# MK70F15 register map
Vendor: Freescale Semiconductor, Inc.; Series: Kinetis_K; File version: 1.6
CPU: CM4 r0p1, little endian, no MPU, FPU, VTOR, 4 interrupt priority bits
Registers are 32-bit, read-write, reset 0x0 unless marked. A register's access mark holds for its fields unless they carry their own. Offsets are from the block's base; [hi:lo] are bit positions; {n}, {i} and the like mark numbered series; 'fields as' and 'values as' point back to an identical list.

## DDR — DRAM Controller
Base 0x400AE000; register names take the prefix DDR_
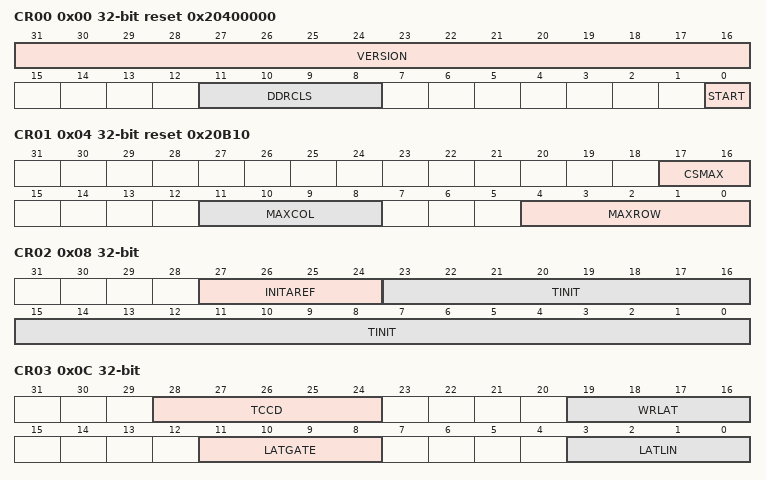
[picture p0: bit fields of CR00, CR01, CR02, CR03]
0x00 CR00 reset 0x20400000 — DDR Control Register 0
  [31:16] VERSION ro
  [11:8] DDRCLS — DRAM Class
    0=DDR; 1=LPDDR; 4=DDR2
  [0] START
0x04 CR01 ro reset 0x20B10 — DDR Control Register 1
  [17:16] CSMAX — Chip Select Maximum
    0=Zero; 1=One; 2=Two
  [11:8] MAXCOL — Maximum Column
    0=0; 1=1; 11=11
  [4:0] MAXROW — Maxmum Row
0x08 CR02 — DDR Control Register 2
  [27:24] INITAREF — Initialization Auto-Refresh
  [23:0] TINIT — Time Initialization
0x0C CR03 — DDR Control Register 3
  [28:24] TCCD — Time CAS-to-CAS Delay
  [19:16] WRLAT — Write Latency
  [11:8] LATGATE — Latency Gate
  [3:0] LATLIN — Latency Linear
    2=1 cycle; 3=1.5 cycles; 15=7.5 cycles
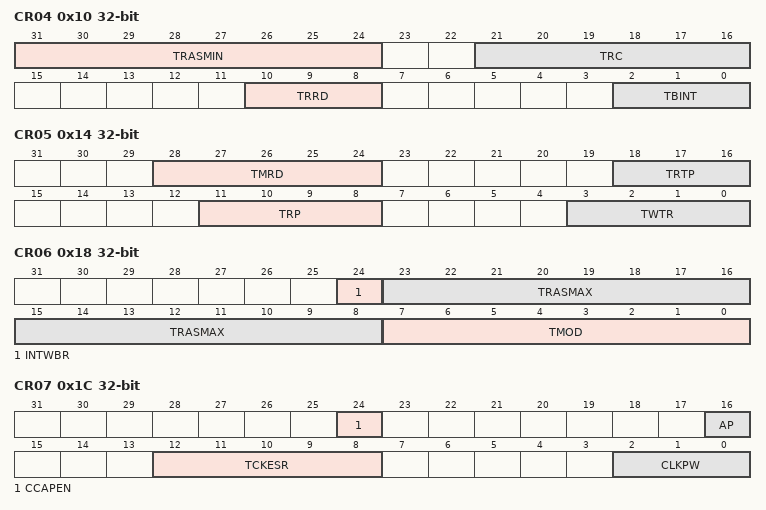
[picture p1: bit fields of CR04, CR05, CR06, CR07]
0x10 CR04 — DDR Control Register 4
  [31:24] TRASMIN — Time RAS Minimum
  [21:16] TRC — Defines the DRAM period between active commands for the same bank (TRC) in cycles.
  [10:8] TRRD — Defines the DRAM activate-to-activate delay for different banks (TRRD) in cycles.
  [2:0] TBINT — Time Burst Interrupt Interval
0x14 CR05 — DDR Control Register 5
  [28:24] TMRD — DRAM TMRD parameter in cycles.
  [18:16] TRTP — Time Read-To-Precharge
  [11:8] TRP — Defines the DRAM precharge command time (TRP) in cycles.
  [3:0] TWTR — Time Write-To-Read
0x18 CR06 — DDR Control Register 6
  [24] INTWBR — Interrupt Write Burst
    0=Read commands cannot interrupt write commands; 1=Read commands can interrupt write commands
  [23:8] TRASMAX — Time Row Access Maximum
  [7:0] TMOD — Time Mode
0x1C CR07 — DDR Control Register 7
  [24] CCAPEN — Concurrent Auto-Precharge Enable
    0=Disabled; 1=Enabled
  [16] AP — Auto Precharge
    0=Disabled; 1=Enabled
  [12:8] TCKESR — Time Clock low Self Refresh
  [2:0] CLKPW — Clock Pulse Width
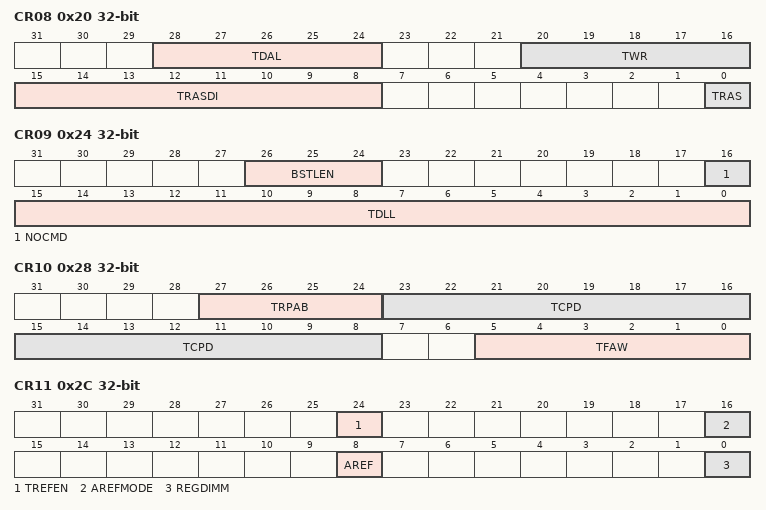
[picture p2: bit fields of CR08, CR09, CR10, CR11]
0x20 CR08 — DDR Control Register 8
  [28:24] TDAL — Defines the auto-precharge write recovery time when auto-precharge is enabled (CR01[AP] is set), in cycles
  [20:16] TWR — Time Write Recovery
  [15:8] TRASDI — Time RAS-to-CAS Delay Interval
  [0] TRAS — Time RAS lockout
0x24 CR09 — DDR Control Register 9
  [26:24] BSTLEN — Burst Length
    1=Two memory words - only applicable if the reduc parameter is set to 'b0 for operation in full datapath mode. Applicable for these memory systems: DDR1 (dram_class = 'b0000) LPDDR1 (dram_class = 'b0001).; 2=Four memory words. Applicable for these memory systems: DDR1 (dram_class = 'b0000) LPDDR1 (dram_class = 'b0001) DDR2 (dram_class = 'b0100).; 3=Eight memory words. Applicable for these memory systems: DDR1 (dram_class = 'b0000) LPDDR1 (dram_class = 'b0001).
  [16] NOCMD — No Command
    0=Issue only REF and PRE commands during DLL initialization of the DRAM devices. If PRE commands are issued before DLL initialization is complete, the command is executed immediately and the DLL initialization continues.; 1=Do not issue any type of command during DLL initialization of the DRAM devices. If any other commands are issued, they are held until DLL initialization completes.
  [15:0] TDLL — Time DLL
0x28 CR10 — DDR Control Register 10
  [27:24] TRPAB — TRP All Bank
  [23:8] TCPD — Time Clock Enable to Precharge Delay
  [5:0] TFAW — Time FAW
0x2C CR11 — DDR Control Register 11
  [24] TREFEN — Enables refresh commands
  [16] AREFMODE — Auto Refresh Mode
  [8] AREF wo — Auto Refresh
  [0] REGDIMM — Registered DIMM
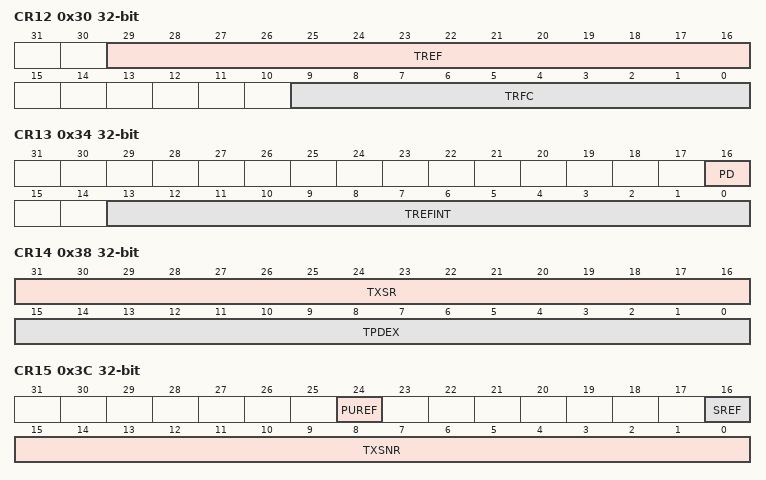
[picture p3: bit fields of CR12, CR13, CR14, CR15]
0x30 CR12 — DDR Control Register 12
  [29:16] TREF — Time Refresh
  [9:0] TRFC — Time Refresh Command
0x34 CR13 — DDR Control Register 13
  [16] PD — Power Down
    0=Enable full power state; 1=The memory controller completes processing of the current burst for the current transaction (if any), issues a precharge all command, and disables the clock enable signal to the DRAM devices. Any subsequent commands in the command queue are suspended until this bit is cleared.
  [13:0] TREFINT — Reserved
0x38 CR14 — DDR Control Register 14
  [31:16] TXSR — Time Exit Self Refresh
  [15:0] TPDEX — Time Power Down Exit
0x3C CR15 — DDR Control Register 15
  [24] PUREF — Power Up Refresh
    0=Disabled; 1=Enabled
  [16] SREF — Self Refresh
  [15:0] TXSNR — TXSNR parameter
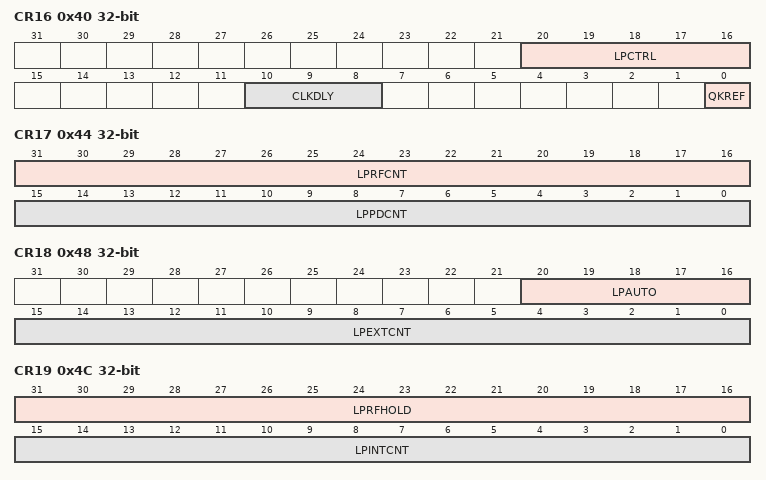
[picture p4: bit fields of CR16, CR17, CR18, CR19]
0x40 CR16 — DDR Control Register 16
  [20:16] LPCTRL — Low Power Control
    0=Disable; 1=Enable
  [10:8] CLKDLY — Clock Delay
  [0] QKREF — Quick Refresh
    0=Continue memory initialization; 1=Interrupt memory initialization and enter self-refresh mode
0x44 CR17 — DDR Control Register 17
  [31:16] LPRFCNT — Low Power Refresh Count
  [15:0] LPPDCNT — Low Power Power Down Count
0x48 CR18 — DDR Control Register 18
  [20:16] LPAUTO — Low Power Auto
  [15:0] LPEXTCNT — Low Power External Count
0x4C CR19 — DDR Control Register 19
  [31:16] LPRFHOLD — Low Power Refresh Hold
  [15:0] LPINTCNT — Low Power Interval Count
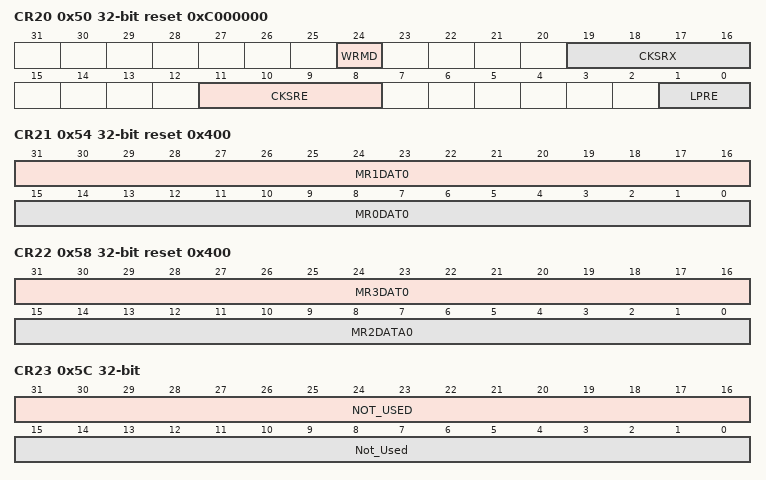
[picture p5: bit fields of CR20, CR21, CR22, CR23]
0x50 CR20 reset 0xC000000 — DDR Control Register 20
  [24] WRMD wo — Write Mode Register
  [19:16] CKSRX — Clock Self Refresh Exit
  [11:8] CKSRE — Clock hold delay on self refresh entry
  [1:0] LPRE — Low Power Refresh enable
    0=Refreshes occur; 1=Refreshes do not occur
0x54 CR21 reset 0x400 — DDR Control Register 21
  [31:16] MR1DAT0 — Data to program into memory mode register 1 for chip select .
  [15:0] MR0DAT0 — Data to program into memory mode register 0 for chip select .
0x58 CR22 reset 0x400 — DDR Control Register 22
  [31:16] MR3DAT0 — Data to program into memory mode register 3 for chip select .
  [15:0] MR2DATA0 — Data to program into memory mode register 2 for chip select .
0x5C CR23 ro — DDR Control Register 23
  [31:16] NOT_USED — Reserved
  [15:0] Not_Used — Reserved
0x60 CR24 ro — DDR Control Register 24
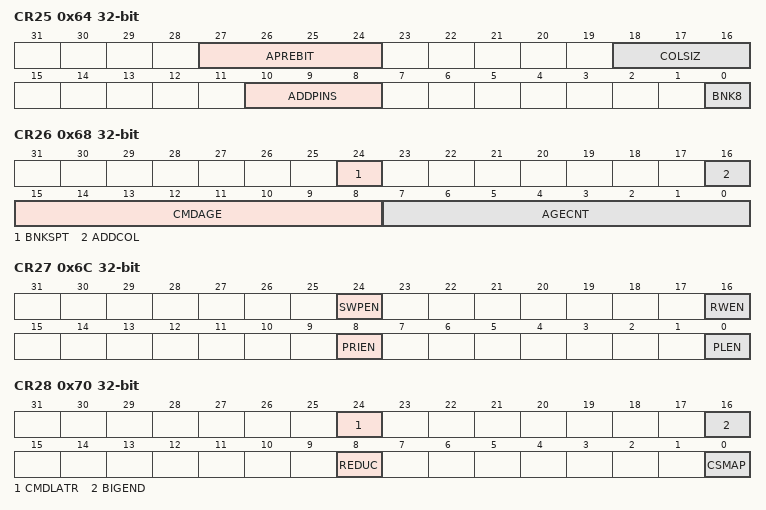
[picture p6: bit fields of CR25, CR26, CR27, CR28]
0x64 CR25 — DDR Control Register 25
  [27:24] APREBIT — Auto Precharge Bit
  [18:16] COLSIZ — Column Size
  [10:8] ADDPINS — Address Pins
  [0] BNK8 — Eight Bank Mode
    0=4 banks; 1=8 banks
0x68 CR26 — DDR Control Register 26
  [24] BNKSPT — Bank Split enable
    0=Disabled; 1=Enabled
  [16] ADDCOL — Address Collision enable
    0=Disable; 1=Enable
  [15:8] CMDAGE — Command Age count
  [7:0] AGECNT — Age Count
0x6C CR27 — DDR Control Register 27
  [24] SWPEN — Swap Enable
    0=Disabled; 1=Enabled
  [16] RWEN — Read Write same Enable
    0=Disabled; 1=Enabled
  [8] PRIEN — Priority Enable
    0=Disabled; 1=Enabled
  [0] PLEN — Placement Enable
    0=Disabled. The command queue is a straight FIFO.; 1=Enabled. The command queue is filled according to the placement logic factors.
0x70 CR28 — DDR Control Register 28
  [24] CMDLATR — Command Latency Reduction Enable
    0=Disable; 1=Enable
  [16] BIGEND — Big Endian Enable
    0=Little endian; 1=Big endian
  [8] REDUC — Controls the width of the memory datapath
    0=16-bit - standard operation using full memory bus; 1=8-bit - Memory datapath width is half of the maximum size. The upper half of the memory busses (DQ, DQS, and DM) are unused and relevant data only exists in the lower half of the busses.
  [0] CSMAP — Chip Select Map
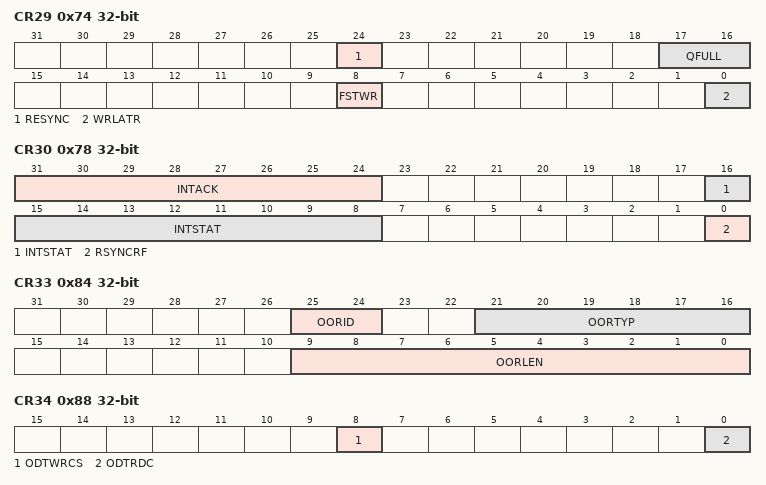
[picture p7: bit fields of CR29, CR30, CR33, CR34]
0x74 CR29 — DDR Control Register 29
  [24] RESYNC wo — Resyncronize
    0=No effect; 1=Initiate
  [17:16] QFULL — Queue Fullness
  [8] FSTWR — Fast Write
    0=The memory controller issues a write command to the DRAM devices when it has received enough data for one DRAM burst. Write data can be sent in any cycle relative to the write command. This mode also allows for multi-word write command data to arrive in non-sequential cycles.; 1=The memory controller issues a write command to the DRAM devices after the first word of the write data is received by the memory controller. The first word can be sent at any time relative to the write command. In this mode, multi-word write command data must be available to the memory controller in sequential cycles.
  [0] WRLATR — Write Latency Reduction enable
    0=Disable; 1=Enable
0x78 CR30 — DDR Control Register 30
  [31:24] INTACK wo — Interupt Acknowlege
    0=No effect; 1=Clear the corresponding bit in INTSTATUS
  [16:8] INTSTAT ro — Interrupt Status
  [0] RSYNCRF — Resynchroize after Refresh
    0=No effect; 1=Enable
0x7C CR31 — DDR Control Register 31
  [8:0] INTMASK — Interrupt Mask
    0=No mask; 1=Mask corresponding interrupt signal
0x80 CR32 ro — DDR Control Register 32
  [31:0] OORAD — Out Of Range Address
0x84 CR33 ro — DDR Control Register 33
  [25:24] OORID — Out Of Range source ID
  [21:16] OORTYP — Out Of Range Type
  [9:0] OORLEN — Out Of Range Length
0x88 CR34 — DDR Control Register 34
  [8] ODTWRCS — ODT Write map CS
  [0] ODTRDC — ODT Read map CS
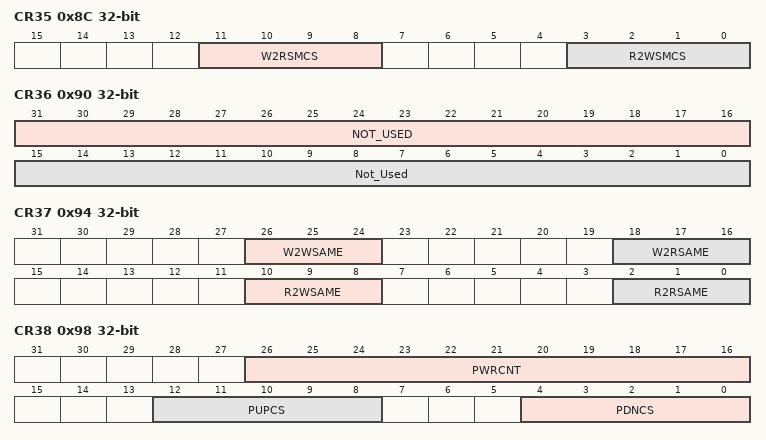
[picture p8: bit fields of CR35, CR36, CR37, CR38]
0x8C CR35 ro — DDR Control Register 35
  [11:8] W2RSMCS — Write To Read Same Chip Select
  [3:0] R2WSMCS — Read To Write Same Chip Select
0x90 CR36 ro — DDR Control Register 36
  [31:16] NOT_USED — Reserved
  [15:0] Not_Used — Reserved
0x94 CR37 — DDR Control Register 37
  [26:24] W2WSAME — W2W Same chip select delay
  [18:16] W2RSAME — W2R Same chip select delay
  [10:8] R2WSAME — R2W Same chip select delay
  [2:0] R2RSAME — R2R Same chip select delay
0x98 CR38 — DDR Control Register 38
  [26:16] PWRCNT — Port 0 Write Count
  [12:8] PUPCS — OCD Pull Up adjustment Chip Select
  [4:0] PDNCS — OCD Pull Down adjustment Chip Select
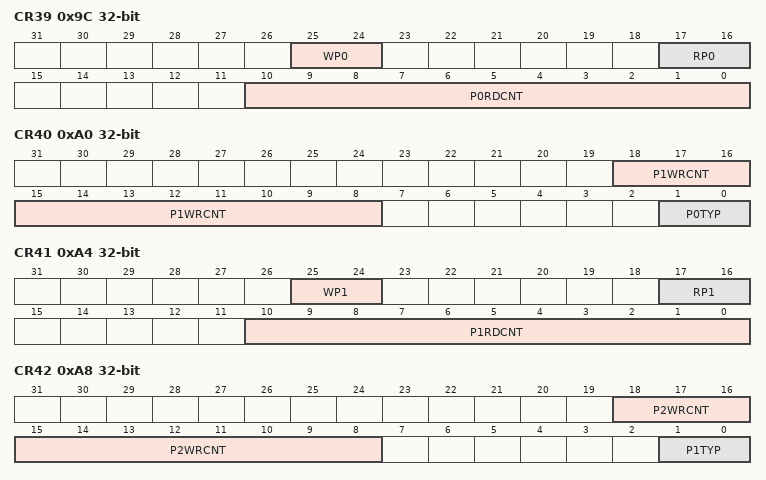
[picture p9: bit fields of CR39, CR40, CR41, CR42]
0x9C CR39 — DDR Control Register 39
  [25:24] WP0 — Port 0 Write command Priority
    0=Highest; 1=01; 2=10; 3=Lowest
  [17:16] RP0 — Port 0 Read command Priority
    0=Highest; 1=01; 2=10; 3=Lowest
  [10:0] P0RDCNT — Port 0 Read command Count
0xA0 CR40 — DDR Control Register 40
  [18:8] P1WRCNT — Port 1 Write command Count
  [1:0] P0TYP — Port 0 Type
0xA4 CR41 — DDR Control Register 41
  [25:24] WP1 — Write command priority Port 1
    0=Highest; 1=01; 2=10; 3=Lowest
  [17:16] RP1 — Read command priority Port 1
    0=Highest; 1=01; 2=10; 3=Lowest
  [10:0] P1RDCNT — Port 1 Read command Count
0xA8 CR42 — DDR Control Register 42
  [18:8] P2WRCNT — Port 2 Write command Count
  [1:0] P1TYP — Port 1 Type
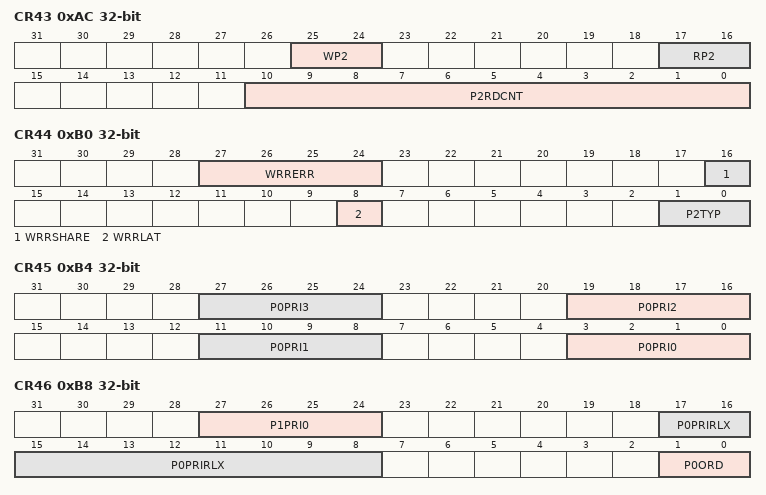
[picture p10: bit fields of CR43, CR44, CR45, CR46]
0xAC CR43 — DDR Control Register 43
  [25:24] WP2 — Write command priority Port 2
    0=Highest; 1=01; 2=10; 3=Lowest
  [17:16] RP2 — Read command priority Port 2
    0=Highest; 1=01; 2=10; 3=Lowest
  [10:0] P2RDCNT — Port 2 Read command Count
0xB0 CR44 — DDR Control Register 44
  [27:24] WRRERR ro — WRR parameters Error
  [16] WRRSHARE — WRR Shared arbitration
    0=Port 0 and port 1 are treated independently for arbitration; 1=Port 0 and port 1 are grouped together for arbitration
  [8] WRRLAT — WRR Latency
    0=Free-running; 1=Limited
  [1:0] P2TYP — Port 2 Type
0xB4 CR45 — DDR Control Register 45
  [all] fields
    0=Lowest; 1=0001; 14=1110; 15=Highest
  [8n+3:8n] P0PRI{n} (n=0..3) — Port 0 Priority {n} commands
0xB8 CR46 — DDR Control Register 46
  [27:24] P1PRI0 — Port 1 Priority 0 commands
    0=Lowest; 1=0001; 14=1110; 15=Highest
  [17:8] P0PRIRLX — Port 0 Priority Relax
  [1:0] P0ORD — Port 0 Order
    0=Highest listing in the scan order; 1=01; 2=10; 3=Lowest listing in the scan order
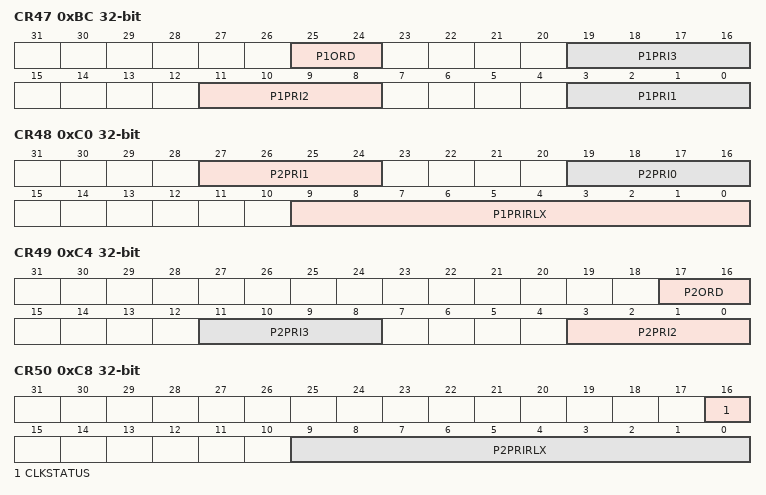
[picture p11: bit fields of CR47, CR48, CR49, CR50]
0xBC CR47 — DDR Control Register 47
  [25:24] P1ORD — Port 1 Order
    0=Highest listing in the scan order; 3=Lowest listing in the scan order
  [19:16] P1PRI3 — Port 1 Priority 3 commands
    0=Lowest; 1=0001; 14=1110; 15=Highest
  [11:8] P1PRI2 — Port 1 Priority 2 commands
    0=Lowest; 1=0001; 14=1110; 15=Highest
  [3:0] P1PRI1 — Port 1 Priority 1 commands
    0=Lowest; 1=0001; 14=1110; 15=Highest
0xC0 CR48 — DDR Control Register 48
  [27:24] P2PRI1 — Port 2 Priority 1 commands
    0=Lowest; 1=0001; 14=1110; 15=Highest
  [19:16] P2PRI0 — Port 2 Priority 0 commands
    0=Lowest; 1=0001; 14=1110; 15=Highest
  [9:0] P1PRIRLX — Port 1 Priority Relax
0xC4 CR49 — DDR Control Register 49
  [17:16] P2ORD — Port 2 Order
    values as CR46.P0ORD
  [11:8] P2PRI3 — Port 2 Priority 3 commands
    0=Lowest; 1=0001; 14=1110; 15=Highest
  [3:0] P2PRI2 — Port 2 Priority 2 commands
    0=Lowest; 1=0001; 14=1110; 15=Highest
0xC8 CR50 — DDR Control Register 50
  [16] CLKSTATUS ro — Clock Status
    0=Disabled; 1=Enabled
  [9:0] P2PRIRLX — Port 2 Priority Relax
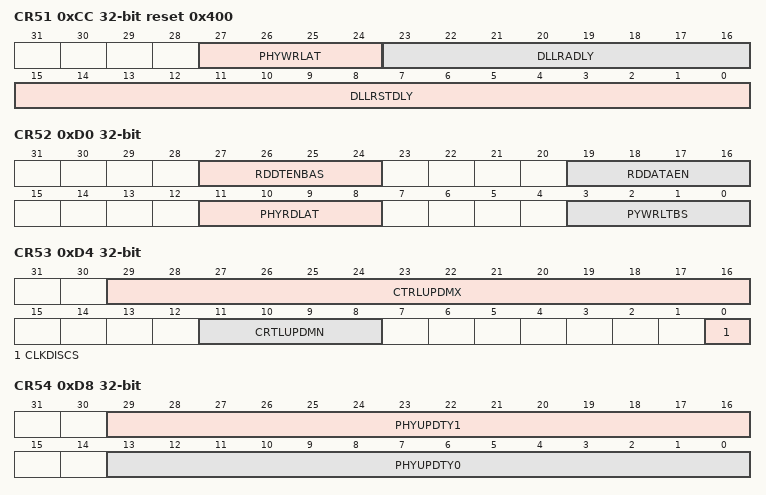
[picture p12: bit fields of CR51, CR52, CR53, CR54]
0xCC CR51 reset 0x400 — DDR Control Register 51
  [27:24] PHYWRLAT ro — PHY Write Latency
  [23:16] DLLRADLY — DLL Reset Adjust Delay
  [15:0] DLLRSTDLY — DLL Reset Delay
0xD0 CR52 — DDR Control Register 52
  [27:24] RDDTENBAS — Read Data Enable Base
  [19:16] RDDATAEN ro — Read Data Enable
  [11:8] PHYRDLAT — PHY Read Latency
  [3:0] PYWRLTBS — PHY Write Latency Base
0xD4 CR53 — DDR Control Register 53
  [29:16] CTRLUPDMX — DFI CRTLUPD Minimum
  [11:8] CRTLUPDMN ro — DFI CRTLUPD Minimum
  [0] CLKDISCS — DRAM Clock Disable for chip select
    0=Memory clock active; 1=Memory clock disabled
0xD8 CR54 — DDR Control Register 54
  [29:16] PHYUPDTY1 — DFI PHYUPD Type 1
  [13:0] PHYUPDTY0 — DFI PHYUPD Type 0
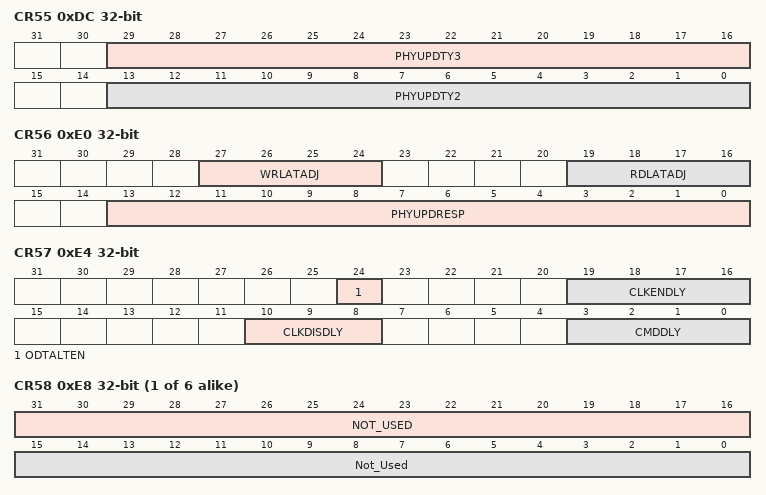
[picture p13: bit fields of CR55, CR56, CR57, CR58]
0xDC CR55 — DDR Control Register 55
  [29:16] PHYUPDTY3 — DFI PHYUPD TYPE3
  [13:0] PHYUPDTY2 — DFI PHYUPD TYPE2
0xE0 CR56 — DDR Control Register 56
  [27:24] WRLATADJ — Write Latency Adjust
  [19:16] RDLATADJ — Read Latency Adjust
  [13:0] PHYUPDRESP — TDFI PHYUPDRESP parameter
0xE4 CR57 — DDR Control Register 57
  [24] ODTALTEN — ODT Alternate Enable
    0=Disable; 1=Enable
  [19:16] CLKENDLY — DFI Clock Enable Delay
  [10:8] CLKDISDLY — DFI Clock Disable Delay
  [3:0] CMDDLY — Command Delay
{0x0+4i} CR{i} ro (i=58..63) — DDR Control Register {i}
  [31:16] NOT_USED — Reserved
  [15:0] Not_Used — Reserved
0x180 RCR — RCR Control Register
  [30] RST wo — Reset
    0=No software reset; 1=Force software reset
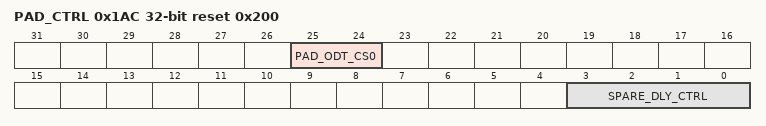
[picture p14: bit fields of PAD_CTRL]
0x1AC PAD_CTRL reset 0x200 — I/O Pad Control Register
  [25:24] PAD_ODT_CS0 — Required to enable ODT and configure ODT resistor value in the pad.
    0=ODT Disabled; 1=75 Ohms; 2=150 Ohms; 3=50 Ohms
  [3:0] SPARE_DLY_CTRL — These SPARE_DLY_CTRL[3:0]bits set the delay chains in the spare logic.
